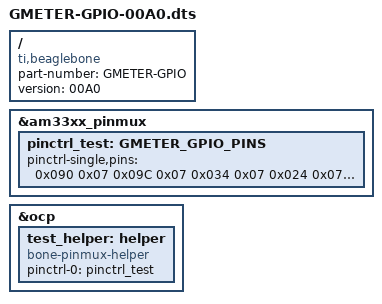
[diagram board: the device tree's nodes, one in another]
/dts-v1/;
/plugin/;

/ {
   compatible = "ti,beaglebone", "ti,beaglebone-black";
   part-number = "GMETER-GPIO";
   version = "00A0";

   fragment@0 {
      target = <&am33xx_pinmux>;

      __overlay__ {
         pinctrl_test: GMETER_GPIO_PINS {
            pinctrl-single,pins = <
               0x090 0x07 /* P8_07 66 OUTPUT MODE7 - Set for output */
               0x09C 0x07 /* P8_09 69 OUTPUT MODE7 - Set for output */
               0x034 0x07 /* P8_11 45 OUTPUT MODE7 - Set for output */
               0x024 0x07 /* P8_13 23 OUTPUT MODE7 - Set for output */
               0x03C 0x07 /* P8_15 47 OUTPUT MODE7 - Set for output */
               0x02C 0x07 /* P8_17 27 OUTPUT MODE7 - Set for output */
               0x082 0x07 /* P8_19 22 OUTPUT MODE7 - Set for output */

               0x070 0x07 /* P9_11 30 OUTPUT MODE7 - Set for output */
            >;
         };
      };
   };
   
   fragment@1 {
      target = <&ocp>;
      __overlay__ {
         test_helper: helper {
            compatible = "bone-pinmux-helper";
            pinctrl-names = "default";
            pinctrl-0 = <&pinctrl_test>;
            status = "okay";
         };
      };
   };
};
